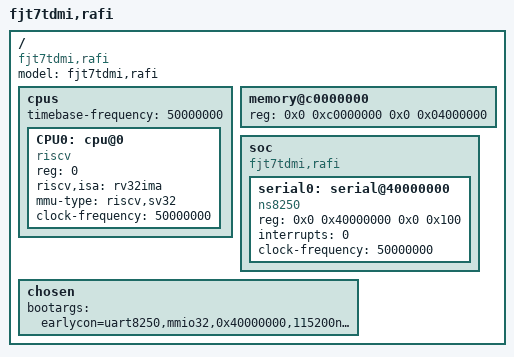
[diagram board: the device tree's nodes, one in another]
/dts-v1/;

/ {
  #address-cells = <2>;
  #size-cells = <2>;
  compatible = "fjt7tdmi,rafi";
  model = "fjt7tdmi,rafi";

  cpus {
    #address-cells = <1>;
    #size-cells = <0>;
    timebase-frequency = <50000000>;
    CPU0: cpu@0 {
      device_type = "cpu";
      reg = <0>;
      status = "okay";
      compatible = "riscv";
      riscv,isa = "rv32ima";
      mmu-type = "riscv,sv32";
      clock-frequency = <50000000>;
    };
  };
  memory@c0000000 {
    device_type = "memory";
    reg = <0x0 0xc0000000 0x0 0x04000000>;
  };
  soc {
    #address-cells = <2>;
    #size-cells = <2>;
    compatible = "fjt7tdmi,rafi", "simple-bus";
    serial0: serial@40000000 {
      device_type = "serial";
      compatible = "ns8250";
      reg = <0x0 0x40000000 0x0 0x100>;
      interrupts = <0>;
      clock-frequency = <50000000>;
    };
  };
  chosen {
    bootargs = "earlycon=uart8250,mmio32,0x40000000,115200n8 console=ttyS0,115200";
  };
};
